AUTOSAR XML (schema 4-2-1)
package /StartApplication/StartApplication_swc/ComponentTypes
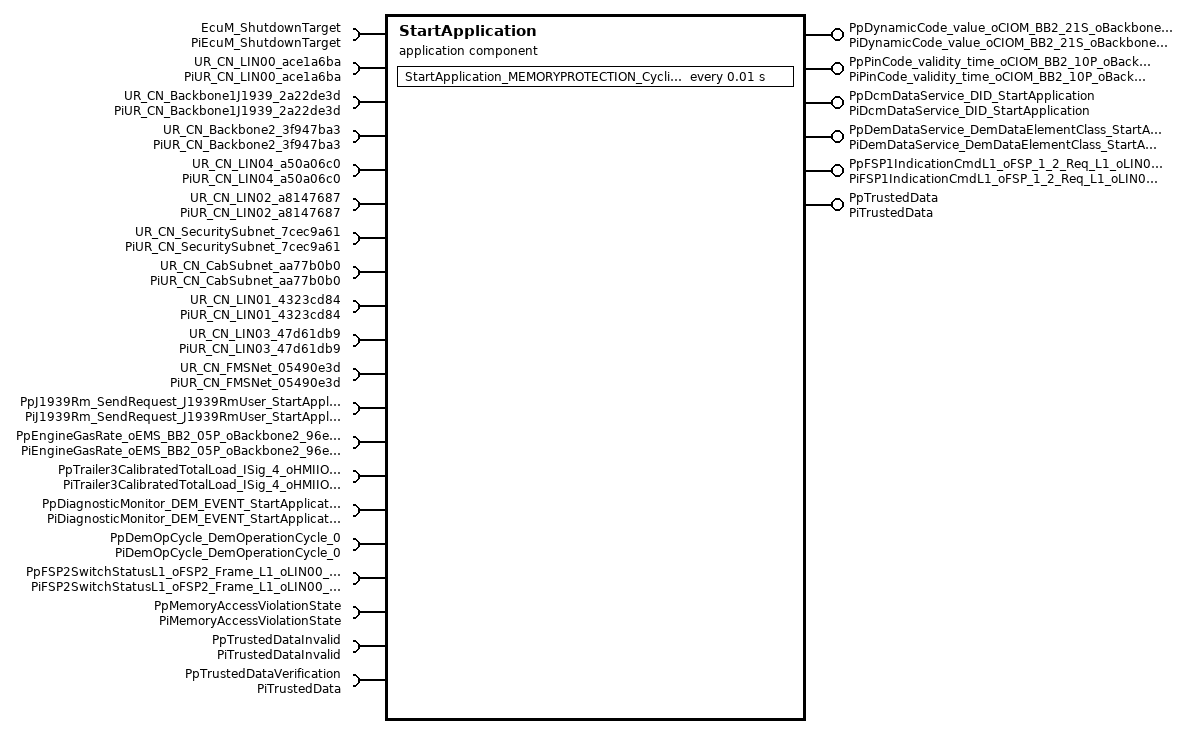
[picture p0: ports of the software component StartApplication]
  application sw component type StartApplication
    14 x require port:
      EcuM_ShutdownTarget: required-interface=PiEcuM_ShutdownTarget
      UR_CN_LIN00_ace1a6ba: required-interface=PiUR_CN_LIN00_ace1a6ba
      UR_CN_Backbone1J1939_2a22de3d: required-interface=PiUR_CN_Backbone1J1939_2a22de3d
      UR_CN_Backbone2_3f947ba3: required-interface=PiUR_CN_Backbone2_3f947ba3
      UR_CN_LIN04_a50a06c0: required-interface=PiUR_CN_LIN04_a50a06c0
      UR_CN_LIN02_a8147687: required-interface=PiUR_CN_LIN02_a8147687
      UR_CN_SecuritySubnet_7cec9a61: required-interface=PiUR_CN_SecuritySubnet_7cec9a61
      UR_CN_CabSubnet_aa77b0b0: required-interface=PiUR_CN_CabSubnet_aa77b0b0
      UR_CN_LIN01_4323cd84: required-interface=PiUR_CN_LIN01_4323cd84
      UR_CN_LIN03_47d61db9: required-interface=PiUR_CN_LIN03_47d61db9
      UR_CN_FMSNet_05490e3d: required-interface=PiUR_CN_FMSNet_05490e3d
      PpJ1939Rm_SendRequest_J1939RmUser_StartApplication: required-interface=PiJ1939Rm_SendRequest_J1939RmUser_StartApplication
      PpEngineGasRate_oEMS_BB2_05P_oBackbone2_96ec243f_Rx: nonqueued-receiver-com-spec{data-element=DeEngineGasRate_oEMS_BB2_05P_oBackbone2_96ec243f_Rx, handle-out-of-range-status=SILENT, init-value=65535}, required-interface=PiEngineGasRate_oEMS_BB2_05P_oBackbone2_96ec243f_Rx
      PpTrailer3CalibratedTotalLoad_ISig_4_oHMIIOM_BB2_15P_oBackbone2_a944db19_Rx: nonqueued-receiver-com-spec{data-element=DeTrailer3CalibratedTotalLoad_ISig_4_oHMIIOM_BB2_15P_oBackbone2_a944db19_Rx, handle-out-of-range-status=SILENT, init-value=65535}, required-interface=PiTrailer3CalibratedTotalLoad_ISig_4_oHMIIOM_BB2_15P_oBackbone2_a944db19_Rx
    provide port PpDynamicCode_value_oCIOM_BB2_21S_oBackbone2_04b10010_Tx: nonqueued-sender-com-spec{data-element=DeDynamicCode_value_oCIOM_BB2_21S_oBackbone2_04b10010_Tx, init-value=4294967295}, provided-interface=PiDynamicCode_value_oCIOM_BB2_21S_oBackbone2_04b10010_Tx
    provide port PpPinCode_validity_time_oCIOM_BB2_10P_oBackbone2_d8b8c81c_Tx: nonqueued-sender-com-spec{data-element=DePinCode_validity_time_oCIOM_BB2_10P_oBackbone2_d8b8c81c_Tx, init-value=255}, provided-interface=PiPinCode_validity_time_oCIOM_BB2_10P_oBackbone2_d8b8c81c_Tx
    require port PpDiagnosticMonitor_DEM_EVENT_StartApplication: required-interface=PiDiagnosticMonitor_DEM_EVENT_StartApplication
    provide port PpDcmDataService_DID_StartApplication: provided-interface=PiDcmDataService_DID_StartApplication
    provide port PpDemDataService_DemDataElementClass_StartApplication: provided-interface=PiDemDataService_DemDataElementClass_StartApplication
    require port PpDemOpCycle_DemOperationCycle_0: required-interface=PiDemOpCycle_DemOperationCycle_0
    provide port PpFSP1IndicationCmdL1_oFSP_1_2_Req_L1_oLIN00_c2c0fe90_Tx: nonqueued-sender-com-spec{data-element=DeFSP1IndicationCmdL1_oFSP_1_2_Req_L1_oLIN00_c2c0fe90_Tx, init-value=0}, provided-interface=PiFSP1IndicationCmdL1_oFSP_1_2_Req_L1_oLIN00_c2c0fe90_Tx
    require port PpFSP2SwitchStatusL1_oFSP2_Frame_L1_oLIN00_ee70e556_Rx: nonqueued-receiver-com-spec{data-element=DeFSP2SwitchStatusL1_oFSP2_Frame_L1_oLIN00_ee70e556_Rx, handle-out-of-range-status=SILENT, init-value=0}, required-interface=PiFSP2SwitchStatusL1_oFSP2_Frame_L1_oLIN00_ee70e556_Rx
    require port PpMemoryAccessViolationState: required-interface=PiMemoryAccessViolationState
    provide port PpTrustedData: nonqueued-sender-com-spec{data-element=DeValue, init-value=0}, provided-interface=PiTrustedData
    require port PpTrustedDataInvalid: required-interface=PiTrustedDataInvalid
    require port PpTrustedDataVerification: nonqueued-receiver-com-spec{data-element=DeValue, handle-out-of-range-status=SILENT, init-value=0}, required-interface=PiTrustedData
    behavior StartApplicationInternalBehavior: handle-termination-and-restart=NO-SUPPORT
      ar-typed-per-instance-memorys:
        14 x data:
          Uptime: type=uint8
          TxCtrlSigValue: type=uint8
          TxDataSigValue: type=uint8
          ActiveComponent: type=EnumActiveComponentType
          COM_RxSigValue0: type=uint16
          COM_TxSigValue0: type=uint8
          NM_ApplState: type=EnumNM_ApplStateType
          NM_ActiveChannelHasFullComRequest: type=uint8
          NM_BusSleepModeTimer: type=uint8
          NM_ActiveComMChannel: type=uint8
          NM_ActiveComMUsers: type=uint32
          DIAG_LastRxData: type=uint8
          COM_RxSigValue1: type=uint8
          COM_TxSigValue1: type=uint16
      4 x timing event:
        Timer_StartApplication_Cyclic1ms: start-on-event=StartApplication_Cyclic1ms, period=0.001
        Timer_StartApplication_Cyclic10ms: start-on-event=StartApplication_Cyclic10ms, period=0.01
        Timer_StartApplication_Cyclic250ms: start-on-event=StartApplication_Cyclic250ms, period=0.25
        Timer_StartApplication_Cyclic1000ms: start-on-event=StartApplication_Cyclic1000ms, period=1
      init event Timer_StartApplication_Init: start-on-event=StartApplication_Init
      data received event DataReceivedEvent_StartApplication_OnDataRec_RxData_PpEngineGasRate_oEMS_BB2_05P_oBackbone2_96ec243f_Rx_DeEngineGasRate_000974b3: start-on-event=StartApplication_OnDataRec_RxData, data=PpEngineGasRate_oEMS_BB2_05P_oBackbone2_96ec243f_Rx.DeEngineGasRate_oEMS_BB2_05P_oBackbone2_96ec243f_Rx
      data received event DataReceivedEvent_StartApplication_OnDataRec_RxCtrl_PpTrailer3CalibratedTotalLoad_ISig_4_oHMIIOM_BB2_15P_oBackbone2_a94_8da52e5b: start-on-event=StartApplication_OnDataRec_RxCtrl, data=PpTrailer3CalibratedTotalLoad_ISig_4_oHMIIOM_BB2_15P_oBackbone2_a944db19_Rx.DeTrailer3CalibratedTotalLoad_ISig_4_oHMIIOM_BB2_15P_oBackbone2_a944db19_Rx
      4 x operation invoked event:
        OpEventStartApplication_DIAG_DcmReadData_ReadData_PpDcmDataService_DID_StartApplication: start-on-event=StartApplication_DIAG_DcmReadData, operation=PpDcmDataService_DID_StartApplication.ReadData
        OpEventStartApplication_DIAG_DcmWriteData_WriteData_PpDcmDataService_DID_StartApplication: start-on-event=StartApplication_DIAG_DcmWriteData, operation=PpDcmDataService_DID_StartApplication.WriteData
        OpEventStartApplication_DIAG_ConditionCheckRead_ConditionCheckRead_PpDcmDataService_DID_StartApplication: start-on-event=StartApplication_DIAG_ConditionCheckRead, operation=PpDcmDataService_DID_StartApplication.ConditionCheckRead
        OpEventStartApplication_DIAG_DemReadData_ReadData_PpDemDataService_DemDataElementClass_StartApplication: start-on-event=StartApplication_DIAG_DemReadData, operation=PpDemDataService_DemDataElementClass_StartApplication.ReadData
      timing event Timer_StartApplication_MEMORYPROTECTION_Cyclic10ms: start-on-event=StartApplication_MEMORYPROTECTION_Cyclic10ms, period=0.01
      explicit-inter-runnable-variables:
        data IrvOccuranceCounterDid: type=uint16, init-value=0
        data IrvMemoryProtectionData: type=DtMemoryProtectionDataElementType, init-value=fields=[0, 0]
      port-api-options:
        enable-take-address=true, indirect-api=false, port=EcuM_ShutdownTarget
        enable-take-address=true, indirect-api=false, port=UR_CN_LIN00_ace1a6ba
        enable-take-address=true, indirect-api=false, port=UR_CN_Backbone1J1939_2a22de3d
        enable-take-address=true, indirect-api=false, port=UR_CN_Backbone2_3f947ba3
        enable-take-address=true, indirect-api=false, port=UR_CN_LIN04_a50a06c0
        enable-take-address=true, indirect-api=false, port=UR_CN_LIN02_a8147687
        enable-take-address=true, indirect-api=false, port=UR_CN_SecuritySubnet_7cec9a61
        enable-take-address=true, indirect-api=false, port=UR_CN_CabSubnet_aa77b0b0
        enable-take-address=true, indirect-api=false, port=UR_CN_LIN01_4323cd84
        enable-take-address=true, indirect-api=false, port=UR_CN_LIN03_47d61db9
        enable-take-address=true, indirect-api=false, port=UR_CN_FMSNet_05490e3d
        enable-take-address=true, indirect-api=false, port=PpJ1939Rm_SendRequest_J1939RmUser_StartApplication
        enable-take-address=true, indirect-api=false, port=PpEngineGasRate_oEMS_BB2_05P_oBackbone2_96ec243f_Rx
        enable-take-address=true, indirect-api=false, port=PpTrailer3CalibratedTotalLoad_ISig_4_oHMIIOM_BB2_15P_oBackbone2_a944db19_Rx
        enable-take-address=true, indirect-api=false, port=PpDynamicCode_value_oCIOM_BB2_21S_oBackbone2_04b10010_Tx
        enable-take-address=true, indirect-api=false, port=PpPinCode_validity_time_oCIOM_BB2_10P_oBackbone2_d8b8c81c_Tx
        enable-take-address=true, indirect-api=false, port=PpDiagnosticMonitor_DEM_EVENT_StartApplication
        enable-take-address=true, indirect-api=false, port=PpDcmDataService_DID_StartApplication
        enable-take-address=true, indirect-api=false, port=PpDemDataService_DemDataElementClass_StartApplication
        enable-take-address=true, indirect-api=false, port=PpDemOpCycle_DemOperationCycle_0
        enable-take-address=true, indirect-api=false, port=PpFSP1IndicationCmdL1_oFSP_1_2_Req_L1_oLIN00_c2c0fe90_Tx
        enable-take-address=true, indirect-api=false, port=PpFSP2SwitchStatusL1_oFSP2_Frame_L1_oLIN00_ee70e556_Rx
        enable-take-address=true, indirect-api=false, port=PpMemoryAccessViolationState
        enable-take-address=true, indirect-api=false, port=PpTrustedData
        enable-take-address=true, indirect-api=false, port=PpTrustedDataInvalid
        enable-take-address=true, indirect-api=false, port=PpTrustedDataVerification
      12 x runnable:
        StartApplication_Cyclic1ms
        StartApplication_Cyclic10ms
        StartApplication_Cyclic250ms
          data-receive-point-by-arguments:
            4 x access:
              DataReceivePointStartApplication_Cyclic250ms_PpEngineGasRate_oEMS_BB2_05P_oBackbone2_96ec243f_Rx_DeEngineGasRate_oEMS_B_ae04b97d: accessed-variable=PpEngineGasRate_oEMS_BB2_05P_oBackbone2_96ec243f_Rx.DeEngineGasRate_oEMS_BB2_05P_oBackbone2_96ec243f_Rx
              DataReceivePointStartApplication_Cyclic250ms_PpTrailer3CalibratedTotalLoad_ISig_4_oHMIIOM_BB2_15P_oBackbone2_a944db19_R_04086d7b: accessed-variable=PpTrailer3CalibratedTotalLoad_ISig_4_oHMIIOM_BB2_15P_oBackbone2_a944db19_Rx.DeTrailer3CalibratedTotalLoad_ISig_4_oHMIIOM_BB2_15P_oBackbone2_a944db19_Rx
              DataReceivePointStartApplication_Cyclic250ms_PpFSP2SwitchStatusL1_oFSP2_Frame_L1_oLIN00_ee70e556_Rx_DeFSP2SwitchStatusL_c96da29d: accessed-variable=PpFSP2SwitchStatusL1_oFSP2_Frame_L1_oLIN00_ee70e556_Rx.DeFSP2SwitchStatusL1_oFSP2_Frame_L1_oLIN00_ee70e556_Rx
              DataReceivePointStartApplication_Cyclic250ms_PpTrustedDataVerification_DeValue: accessed-variable=PpTrustedDataVerification.DeValue
          data-send-points:
            access DataSendPointStartApplication_Cyclic250ms_PpDynamicCode_value_oCIOM_BB2_21S_oBackbone2_04b10010_Tx_DeDynamicCode_value_b269f14a: accessed-variable=PpDynamicCode_value_oCIOM_BB2_21S_oBackbone2_04b10010_Tx.DeDynamicCode_value_oCIOM_BB2_21S_oBackbone2_04b10010_Tx
            access DataSendPointStartApplication_Cyclic250ms_PpPinCode_validity_time_oCIOM_BB2_10P_oBackbone2_d8b8c81c_Tx_DePinCode_validi_57f892c7: accessed-variable=PpPinCode_validity_time_oCIOM_BB2_10P_oBackbone2_d8b8c81c_Tx.DePinCode_validity_time_oCIOM_BB2_10P_oBackbone2_d8b8c81c_Tx
            access DataSendPointStartApplication_Cyclic250ms_PpFSP1IndicationCmdL1_oFSP_1_2_Req_L1_oLIN00_c2c0fe90_Tx_DeFSP1IndicationCmdL_f76876c0: accessed-variable=PpFSP1IndicationCmdL1_oFSP_1_2_Req_L1_oLIN00_c2c0fe90_Tx.DeFSP1IndicationCmdL1_oFSP_1_2_Req_L1_oLIN00_c2c0fe90_Tx
          read-local-variables:
            access StartApplication_Cyclic250ms_IrvOccuranceCounterDid_DIRECT_READ: accessed-variable=IrvOccuranceCounterDid
          22 x sync call, all with timeout=0:
            OpServerCallStartApplication_Cyclic250ms_GetCurrentComMode_UR_CN_LIN00_ace1a6ba: operation=UR_CN_LIN00_ace1a6ba.GetCurrentComMode
            OpServerCallStartApplication_Cyclic250ms_RequestComMode_UR_CN_LIN00_ace1a6ba: operation=UR_CN_LIN00_ace1a6ba.RequestComMode
            OpServerCallStartApplication_Cyclic250ms_GetCurrentComMode_UR_CN_Backbone1J1939_2a22de3d: operation=UR_CN_Backbone1J1939_2a22de3d.GetCurrentComMode
            OpServerCallStartApplication_Cyclic250ms_RequestComMode_UR_CN_Backbone1J1939_2a22de3d: operation=UR_CN_Backbone1J1939_2a22de3d.RequestComMode
            OpServerCallStartApplication_Cyclic250ms_GetCurrentComMode_UR_CN_Backbone2_3f947ba3: operation=UR_CN_Backbone2_3f947ba3.GetCurrentComMode
            OpServerCallStartApplication_Cyclic250ms_RequestComMode_UR_CN_Backbone2_3f947ba3: operation=UR_CN_Backbone2_3f947ba3.RequestComMode
            OpServerCallStartApplication_Cyclic250ms_GetCurrentComMode_UR_CN_LIN04_a50a06c0: operation=UR_CN_LIN04_a50a06c0.GetCurrentComMode
            OpServerCallStartApplication_Cyclic250ms_RequestComMode_UR_CN_LIN04_a50a06c0: operation=UR_CN_LIN04_a50a06c0.RequestComMode
            OpServerCallStartApplication_Cyclic250ms_GetCurrentComMode_UR_CN_LIN02_a8147687: operation=UR_CN_LIN02_a8147687.GetCurrentComMode
            OpServerCallStartApplication_Cyclic250ms_RequestComMode_UR_CN_LIN02_a8147687: operation=UR_CN_LIN02_a8147687.RequestComMode
            OpServerCallStartApplication_Cyclic250ms_GetCurrentComMode_UR_CN_SecuritySubnet_7cec9a61: operation=UR_CN_SecuritySubnet_7cec9a61.GetCurrentComMode
            OpServerCallStartApplication_Cyclic250ms_RequestComMode_UR_CN_SecuritySubnet_7cec9a61: operation=UR_CN_SecuritySubnet_7cec9a61.RequestComMode
            OpServerCallStartApplication_Cyclic250ms_GetCurrentComMode_UR_CN_CabSubnet_aa77b0b0: operation=UR_CN_CabSubnet_aa77b0b0.GetCurrentComMode
            OpServerCallStartApplication_Cyclic250ms_RequestComMode_UR_CN_CabSubnet_aa77b0b0: operation=UR_CN_CabSubnet_aa77b0b0.RequestComMode
            OpServerCallStartApplication_Cyclic250ms_GetCurrentComMode_UR_CN_LIN01_4323cd84: operation=UR_CN_LIN01_4323cd84.GetCurrentComMode
            OpServerCallStartApplication_Cyclic250ms_RequestComMode_UR_CN_LIN01_4323cd84: operation=UR_CN_LIN01_4323cd84.RequestComMode
            OpServerCallStartApplication_Cyclic250ms_GetCurrentComMode_UR_CN_LIN03_47d61db9: operation=UR_CN_LIN03_47d61db9.GetCurrentComMode
            OpServerCallStartApplication_Cyclic250ms_RequestComMode_UR_CN_LIN03_47d61db9: operation=UR_CN_LIN03_47d61db9.RequestComMode
            OpServerCallStartApplication_Cyclic250ms_GetCurrentComMode_UR_CN_FMSNet_05490e3d: operation=UR_CN_FMSNet_05490e3d.GetCurrentComMode
            OpServerCallStartApplication_Cyclic250ms_RequestComMode_UR_CN_FMSNet_05490e3d: operation=UR_CN_FMSNet_05490e3d.RequestComMode
            OpServerCallStartApplication_Cyclic250ms_SendRequest_PpJ1939Rm_SendRequest_J1939RmUser_StartApplication: operation=PpJ1939Rm_SendRequest_J1939RmUser_StartApplication.SendRequest
            OpServerCallStartApplication_Cyclic250ms_GetState_PpMemoryAccessViolationState: operation=PpMemoryAccessViolationState.GetState
        StartApplication_Cyclic1000ms
        StartApplication_Init: can-be-invoked-concurrently=true
          10 x sync call, all with timeout=0:
            OpServerCallStartApplication_Init_RequestComMode_UR_CN_LIN00_ace1a6ba: operation=UR_CN_LIN00_ace1a6ba.RequestComMode
            OpServerCallStartApplication_Init_RequestComMode_UR_CN_Backbone1J1939_2a22de3d: operation=UR_CN_Backbone1J1939_2a22de3d.RequestComMode
            OpServerCallStartApplication_Init_RequestComMode_UR_CN_Backbone2_3f947ba3: operation=UR_CN_Backbone2_3f947ba3.RequestComMode
            OpServerCallStartApplication_Init_RequestComMode_UR_CN_LIN04_a50a06c0: operation=UR_CN_LIN04_a50a06c0.RequestComMode
            OpServerCallStartApplication_Init_RequestComMode_UR_CN_LIN02_a8147687: operation=UR_CN_LIN02_a8147687.RequestComMode
            OpServerCallStartApplication_Init_RequestComMode_UR_CN_SecuritySubnet_7cec9a61: operation=UR_CN_SecuritySubnet_7cec9a61.RequestComMode
            OpServerCallStartApplication_Init_RequestComMode_UR_CN_CabSubnet_aa77b0b0: operation=UR_CN_CabSubnet_aa77b0b0.RequestComMode
            OpServerCallStartApplication_Init_RequestComMode_UR_CN_LIN01_4323cd84: operation=UR_CN_LIN01_4323cd84.RequestComMode
            OpServerCallStartApplication_Init_RequestComMode_UR_CN_LIN03_47d61db9: operation=UR_CN_LIN03_47d61db9.RequestComMode
            OpServerCallStartApplication_Init_RequestComMode_UR_CN_FMSNet_05490e3d: operation=UR_CN_FMSNet_05490e3d.RequestComMode
        StartApplication_OnDataRec_RxCtrl
          data-receive-point-by-arguments:
            access DataReceivePointStartApplication_OnDataRec_RxCtrl_PpTrailer3CalibratedTotalLoad_ISig_4_oHMIIOM_BB2_15P_oBackbone2_a944d_33d96471: accessed-variable=PpTrailer3CalibratedTotalLoad_ISig_4_oHMIIOM_BB2_15P_oBackbone2_a944db19_Rx.DeTrailer3CalibratedTotalLoad_ISig_4_oHMIIOM_BB2_15P_oBackbone2_a944db19_Rx
          data-send-points:
            access DataSendPointStartApplication_OnDataRec_RxCtrl_PpDynamicCode_value_oCIOM_BB2_21S_oBackbone2_04b10010_Tx_DeDynamicCode_v_6366352b: accessed-variable=PpDynamicCode_value_oCIOM_BB2_21S_oBackbone2_04b10010_Tx.DeDynamicCode_value_oCIOM_BB2_21S_oBackbone2_04b10010_Tx
          sync call OpServerCallStartApplication_OnDataRec_RxCtrl_SetOperationCycleState_PpDemOpCycle_DemOperationCycle_0: operation=PpDemOpCycle_DemOperationCycle_0.SetOperationCycleState, timeout=0
        StartApplication_OnDataRec_RxData
          data-receive-point-by-arguments:
            access DataReceivePointStartApplication_OnDataRec_RxData_PpEngineGasRate_oEMS_BB2_05P_oBackbone2_96ec243f_Rx_DeEngineGasRate_o_5e0bb4c8: accessed-variable=PpEngineGasRate_oEMS_BB2_05P_oBackbone2_96ec243f_Rx.DeEngineGasRate_oEMS_BB2_05P_oBackbone2_96ec243f_Rx
          data-send-points:
            access DataSendPointStartApplication_OnDataRec_RxData_PpDynamicCode_value_oCIOM_BB2_21S_oBackbone2_04b10010_Tx_DeDynamicCode_v_8dc24bf2: accessed-variable=PpDynamicCode_value_oCIOM_BB2_21S_oBackbone2_04b10010_Tx.DeDynamicCode_value_oCIOM_BB2_21S_oBackbone2_04b10010_Tx
            access DataSendPointStartApplication_OnDataRec_RxData_PpTrustedData_DeValue: accessed-variable=PpTrustedData.DeValue
          read-local-variables:
            access StartApplication_OnDataRec_RxData_IrvOccuranceCounterDid_DIRECT_READ: accessed-variable=IrvOccuranceCounterDid
          sync call OpServerCallStartApplication_OnDataRec_RxData_SelectShutdownTarget_EcuM_ShutdownTarget: operation=EcuM_ShutdownTarget.SelectShutdownTarget, timeout=0
          sync call OpServerCallStartApplication_OnDataRec_RxData_SetEventStatus_PpDiagnosticMonitor_DEM_EVENT_StartApplication: operation=PpDiagnosticMonitor_DEM_EVENT_StartApplication.SetEventStatus, timeout=0
          sync call OpServerCallStartApplication_OnDataRec_RxData_Reset_PpMemoryAccessViolationState: operation=PpMemoryAccessViolationState.Reset, timeout=0
          written-local-variables:
            access StartApplication_OnDataRec_RxData_IrvOccuranceCounterDid_DIRECT_WRITE: accessed-variable=IrvOccuranceCounterDid
            access StartApplication_OnDataRec_RxData_IrvMemoryProtectionData_DIRECT_WRITE: accessed-variable=IrvMemoryProtectionData
        StartApplication_DIAG_DcmReadData: can-be-invoked-concurrently=true
          read-local-variables:
            access StartApplication_DIAG_DcmReadData_IrvOccuranceCounterDid_DIRECT_READ: accessed-variable=IrvOccuranceCounterDid
        StartApplication_DIAG_DcmWriteData: can-be-invoked-concurrently=true
          written-local-variables:
            access StartApplication_DIAG_DcmWriteData_IrvOccuranceCounterDid_DIRECT_WRITE: accessed-variable=IrvOccuranceCounterDid
        StartApplication_DIAG_ConditionCheckRead: can-be-invoked-concurrently=true
        StartApplication_DIAG_DemReadData: can-be-invoked-concurrently=true
          read-local-variables:
            access StartApplication_DIAG_DemReadData_IrvOccuranceCounterDid_DIRECT_READ: accessed-variable=IrvOccuranceCounterDid
        StartApplication_MEMORYPROTECTION_Cyclic10ms
          read-local-variables:
            access StartApplication_MEMORYPROTECTION_Cyclic10ms_IrvMemoryProtectionData_DIRECT_READ: accessed-variable=IrvMemoryProtectionData
          sync call OpServerCallStartApplication_MEMORYPROTECTION_Cyclic10ms_Write_PpTrustedDataInvalid: operation=PpTrustedDataInvalid.Write, timeout=0
          written-local-variables:
            access StartApplication_MEMORYPROTECTION_Cyclic10ms_IrvMemoryProtectionData_DIRECT_WRITE: accessed-variable=IrvMemoryProtectionData
  swc implementation StartApplicationImplementation: programming-language=C, behavior=StartApplicationInternalBehavior
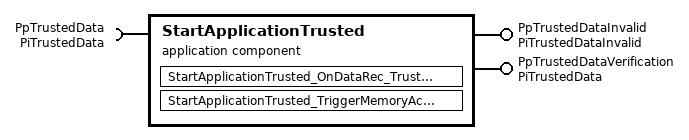
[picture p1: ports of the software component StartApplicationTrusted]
  application sw component type StartApplicationTrusted
    require port PpTrustedData: nonqueued-receiver-com-spec{data-element=DeValue, handle-out-of-range-status=SILENT, init-value=0}, required-interface=PiTrustedData
    provide port PpTrustedDataInvalid: server-com-spec{operation=Write, queue-length=1}, provided-interface=PiTrustedDataInvalid
    provide port PpTrustedDataVerification: nonqueued-sender-com-spec{data-element=DeValue, init-value=0}, provided-interface=PiTrustedData
    behavior StartApplicationTrustedInternalBehavior: handle-termination-and-restart=NO-SUPPORT
      data received event DataReceivedEvent_StartApplicationTrusted_OnDataRec_TrustedData_PpTrustedData_DeValue: start-on-event=StartApplicationTrusted_OnDataRec_TrustedData, data=PpTrustedData.DeValue
      operation invoked event OpEventStartApplicationTrusted_TriggerMemoryAccesViolation_Write_PpTrustedDataInvalid: start-on-event=StartApplicationTrusted_TriggerMemoryAccesViolation, operation=PpTrustedDataInvalid.Write
      explicit-inter-runnable-variables:
        data IrvValue: type=uint8, init-value=0
      port-api-options:
        enable-take-address=true, indirect-api=false, port=PpTrustedData
        enable-take-address=true, indirect-api=false, port=PpTrustedDataInvalid
        enable-take-address=true, indirect-api=false, port=PpTrustedDataVerification
      runnable StartApplicationTrusted_OnDataRec_TrustedData
        data-receive-point-by-arguments:
          access DataReceivePointStartApplicationTrusted_OnDataRec_TrustedData_PpTrustedData_DeValue: accessed-variable=PpTrustedData.DeValue
        data-send-points:
          access DataSendPointStartApplicationTrusted_OnDataRec_TrustedData_PpTrustedDataVerification_DeValue: accessed-variable=PpTrustedDataVerification.DeValue
        read-local-variables:
          access StartApplicationTrusted_OnDataRec_TrustedData_IrvValue_DIRECT_READ: accessed-variable=IrvValue
        written-local-variables:
          access StartApplicationTrusted_OnDataRec_TrustedData_IrvValue_DIRECT_WRITE: accessed-variable=IrvValue
      runnable StartApplicationTrusted_TriggerMemoryAccesViolation
        data-send-points:
          access DataSendPointStartApplicationTrusted_TriggerMemoryAccesViolation_PpTrustedDataVerification_DeValue: accessed-variable=PpTrustedDataVerification.DeValue
        read-local-variables:
          access StartApplicationTrusted_TriggerMemoryAccesViolation_IrvValue_DIRECT_READ: accessed-variable=IrvValue
        written-local-variables:
          access StartApplicationTrusted_TriggerMemoryAccesViolation_IrvValue_DIRECT_WRITE: accessed-variable=IrvValue
  swc implementation StartApplicationTrustedImplementation: programming-language=C, behavior=StartApplicationTrustedInternalBehavior
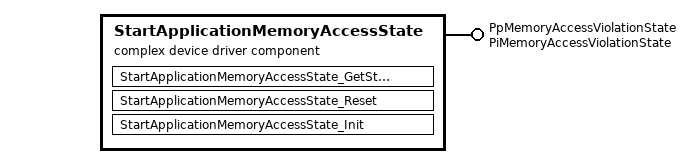
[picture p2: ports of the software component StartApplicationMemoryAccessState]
  complex device driver sw component type StartApplicationMemoryAccessState
    provide port PpMemoryAccessViolationState: provided-com-specs=[{operation=GetState, queue-length=1}, {operation=Reset, queue-length=1}], provided-interface=PiMemoryAccessViolationState
    behavior StartApplicationMemoryAccessStateInternalBehavior: handle-termination-and-restart=NO-SUPPORT, port-api-option{enable-take-address=true, indirect-api=false, port=PpMemoryAccessViolationState}
      ar-typed-per-instance-memorys:
        data PimMemoryAccessState: type=boolean
      operation invoked event OpEventStartApplicationMemoryAccessState_GetState_GetState_PpMemoryAccessViolationState: start-on-event=StartApplicationMemoryAccessState_GetState, operation=PpMemoryAccessViolationState.GetState
      operation invoked event OpEventStartApplicationMemoryAccessState_Reset_Reset_PpMemoryAccessViolationState: start-on-event=StartApplicationMemoryAccessState_Reset, operation=PpMemoryAccessViolationState.Reset
      init event Timer_StartApplicationMemoryAccessState_Init: start-on-event=StartApplicationMemoryAccessState_Init
      runnable StartApplicationMemoryAccessState_GetState
      runnable StartApplicationMemoryAccessState_Reset
      runnable StartApplicationMemoryAccessState_Init: can-be-invoked-concurrently=true
  swc implementation StartApplicationMemoryAccessStateImplementation: programming-language=C, behavior=StartApplicationMemoryAccessStateInternalBehavior
package /StartApplication/StartApplication_swc/DataTypes
  15 x impl type:
    EcuM_StateType:
      compu {15=ECUM_SUBSTATE_MASK, 16=ECUM_STATE_STARTUP, 17=ECUM_STATE_STARTUP_ONE, 18=ECUM_STATE_STARTUP_TWO, 32=ECUM_STATE_WAKEUP, 33=ECUM_STATE_WAKEUP_ONE, 34=ECUM_STATE_WAKEUP_VALIDATION, 35=ECUM_STATE_WAKEUP_REACTION, 36=ECUM_STATE_WAKEUP_TWO, 37=ECUM_STATE_WAKEUP_WAKESLEEP, 38=ECUM_STATE_WAKEUP_TTII, 48=ECUM_STATE_RUN, 50=ECUM_STATE_APP_RUN, 51=ECUM_STATE_APP_POST_RUN, 64=ECUM_STATE_SHUTDOWN, 68=ECUM_STATE_PREP_SHUTDOWN, 73=ECUM_STATE_GO_SLEEP, 77=ECUM_STATE_GO_OFF_ONE, 78=ECUM_STATE_GO_OFF_TWO, 80=ECUM_STATE_SLEEP, 128=ECUM_STATE_OFF, 144=ECUM_STATE_RESET}
      range raw 0..144
      implementation-data-type=uint8
    EcuM_SleepModeType: implementation-data-type=uint8
    EcuM_ShutdownCauseType: compu {0=ECUM_CAUSE_UNKNOWN, 1=ECUM_CAUSE_ECU_STATE, 2=ECUM_CAUSE_WDGM, 3=ECUM_CAUSE_DCM}, range raw 0..3, implementation-data-type=uint8
    ComM_ModeType: compu {0=COMM_NO_COMMUNICATION, 1=COMM_SILENT_COMMUNICATION, 2=COMM_FULL_COMMUNICATION}, range raw 0..2, implementation-data-type=uint8
    NetworkHandleType: implementation-data-type=uint8, type-emitter=StartApplication
    J1939Rm_ExtIdType: compu {0=J1939RM_EXTID_NONE, 1=J1939RM_EXTID_ONE, 2=J1939RM_EXTID_TWO, 3=J1939RM_EXTID_THREE, 4=J1939RM_EXTID_GF}, range raw 0..4, implementation-data-type=uint8
    J1939Rm_ExtIdInfoType: category=STRUCTURE
      4 x element, all with category=TYPE_REFERENCE:
        ExtIdType: implementation-data-type=J1939Rm_ExtIdType
        ExtId{1..3}: implementation-data-type=uint8
    EnumNM_ApplStateType: compu {0=NM_APPL_STATE_FULL_COMM_EXTERN, 1=NM_APPL_STATE_FULL_COMM_INTERN, 2=NM_APPL_STATE_NO_COMM_EXTERN}, range raw 0..2, implementation-data-type=uint8
    Dem_EventStatusType: compu {0=DEM_EVENT_STATUS_PASSED, 1=DEM_EVENT_STATUS_FAILED, 2=DEM_EVENT_STATUS_PREPASSED, 3=DEM_EVENT_STATUS_PREFAILED, 4=DEM_EVENT_STATUS_FDC_THRESHOLD_REACHED}, range raw 0..4, implementation-data-type=uint8
    Dcm_Data2ByteType: category=ARRAY, sw-calibration-access=READ-ONLY
      element Dcm_Data2ByteTypeElement: array-size=2, array-size-semantics=FIXED-SIZE, implementation-data-type=uint8
    Dcm_NegativeResponseCodeType:
      compu {0=DCM_E_POSITIVERESPONSE, 16=DCM_E_GENERALREJECT, 17=DCM_E_SERVICENOTSUPPORTED, 18=DCM_E_SUBFUNCTIONNOTSUPPORTED, 19=DCM_E_INCORRECTMESSAGELENGTHORINVALIDFORMAT, 20=DCM_E_RESPONSETOOLONG, 33=DCM_E_BUSYREPEATREQUEST, 34=DCM_E_CONDITIONSNOTCORRECT, 36=DCM_E_REQUESTSEQUENCEERROR, 37=DCM_E_NORESPONSEFROMSUBNETCOMPONENT, 38=DCM_E_FAILUREPREVENTSEXECUTIONOFREQUESTEDACTION, 49=DCM_E_REQUESTOUTOFRANGE, 51=DCM_E_SECURITYACCESSDENIED, 53=DCM_E_INVALIDKEY, 54=DCM_E_EXCEEDNUMBEROFATTEMPTS, 55=DCM_E_REQUIREDTIMEDELAYNOTEXPIRED, 112=DCM_E_UPLOADDOWNLOADNOTACCEPTED, 113=DCM_E_TRANSFERDATASUSPENDED, 114=DCM_E_GENERALPROGRAMMINGFAILURE, 115=DCM_E_WRONGBLOCKSEQUENCECOUNTER, 120=DCM_E_REQUESTCORRECTLYRECEIVEDRESPONSEPENDING, 126=DCM_E_SUBFUNCTIONNOTSUPPORTEDINACTIVESESSION, 127=DCM_E_SERVICENOTSUPPORTEDINACTIVESESSION, 129=DCM_E_RPMTOOHIGH, 130=DCM_E_RPMTOOLOW, 131=DCM_E_ENGINEISRUNNING, 132=DCM_E_ENGINEISNOTRUNNING, 133=DCM_E_ENGINERUNTIMETOOLOW, 134=DCM_E_TEMPERATURETOOHIGH, 135=DCM_E_TEMPERATURETOOLOW, 136=DCM_E_VEHICLESPEEDTOOHIGH, 137=DCM_E_VEHICLESPEEDTOOLOW, 138=DCM_E_THROTTLE_PEDALTOOHIGH, 139=DCM_E_THROTTLE_PEDALTOOLOW, 140=DCM_E_TRANSMISSIONRANGENOTINNEUTRAL, 141=DCM_E_TRANSMISSIONRANGENOTINGEAR, 143=DCM_E_BRAKESWITCH_NOTCLOSED, 144=DCM_E_SHIFTERLEVERNOTINPARK, 145=DCM_E_TORQUECONVERTERCLUTCHLOCKED, 146=DCM_E_VOLTAGETOOHIGH, 147=DCM_E_VOLTAGETOOLOW}
      range raw 0..147
      implementation-data-type=uint8
    DataArray_Type_2: category=ARRAY, sw-calibration-access=READ-ONLY
      element DataArray_Type_2Element: array-size=2, array-size-semantics=FIXED-SIZE, implementation-data-type=uint8
    Dem_OperationCycleStateType: compu {0=DEM_CYCLE_STATE_START, 1=DEM_CYCLE_STATE_END}, range raw 0..1, implementation-data-type=uint8
    DtMemoryProtectionDataElementType: category=STRUCTURE
      element Value: implementation-data-type=uint8
      element InvalidAccess: implementation-data-type=boolean
    EnumActiveComponentType: compu {0=STARTAPPLICATION_ACTIVE_COMPONENT_COM_RXTX, 2=STARTAPPLICATION_ACTIVE_COMPONENT_DIAG, 3=STARTAPPLICATION_ACTIVE_COMPONENT_COM_TXONLY, 9=STARTAPPLICATION_ACTIVE_COMPONENT_MEMORYPROTECTION, 10=STARTAPPLICATION_ACTIVE_COMPONENT_NM, 255=STARTAPPLICATION_ACTIVE_COMPONENT_INVALID}, range raw 0..255, implementation-data-type=uint8
package /StartApplication/StartApplication_swc/Interfaces
  sender receiver interface PiGeneric
    data DeGeneric: type=uint8
  12 x client server interface, all with is-service=true, service-kind=VENDOR-SPECIFIC:
    PiEcuM_ShutdownTarget
      5 x operation, all with possible-error=PiEcuM_ShutdownTarget/E_NOT_OK:
        SelectShutdownTarget
          arg targetState: type=EcuM_StateType, direction=IN
          arg resetSleepMode: type=EcuM_SleepModeType, direction=IN
        GetShutdownTarget
          arg target: type=EcuM_StateType, direction=OUT
          arg resetSleepMode: type=EcuM_SleepModeType, direction=OUT
        GetLastShutdownTarget
          arg target: type=EcuM_StateType, direction=OUT
          arg resetSleepMode: type=EcuM_SleepModeType, direction=OUT
        SelectShutdownCause
          arg shutdownCause: type=EcuM_ShutdownCauseType, direction=IN
        GetShutdownCause
          arg shutdownCause: type=EcuM_ShutdownCauseType, direction=OUT
      error E_NOT_OK: error-code=1
    PiUR_CN_LIN00_ace1a6ba
      4 x operation:
        GetCurrentComMode: possible-error=PiUR_CN_LIN00_ace1a6ba/E_NOT_OK
          arg ComMode: type=ComM_ModeType, direction=OUT
        GetMaxComMode: possible-error=PiUR_CN_LIN00_ace1a6ba/E_NOT_OK
          arg ComMode: type=ComM_ModeType, direction=OUT
        GetRequestedComMode: possible-error=PiUR_CN_LIN00_ace1a6ba/E_NOT_OK
          arg ComMode: type=ComM_ModeType, direction=OUT
        RequestComMode: possible-error=[PiUR_CN_LIN00_ace1a6ba/E_NOT_OK, PiUR_CN_LIN00_ace1a6ba/E_MODE_LIMITATION]
          arg ComMode: type=ComM_ModeType, direction=IN
      error E_NOT_OK: error-code=1
      error E_MODE_LIMITATION: error-code=2
    PiUR_CN_Backbone1J1939_2a22de3d
      4 x operation:
        GetCurrentComMode: possible-error=PiUR_CN_Backbone1J1939_2a22de3d/E_NOT_OK
          arg ComMode: type=ComM_ModeType, direction=OUT
        GetMaxComMode: possible-error=PiUR_CN_Backbone1J1939_2a22de3d/E_NOT_OK
          arg ComMode: type=ComM_ModeType, direction=OUT
        GetRequestedComMode: possible-error=PiUR_CN_Backbone1J1939_2a22de3d/E_NOT_OK
          arg ComMode: type=ComM_ModeType, direction=OUT
        RequestComMode: possible-error=[PiUR_CN_Backbone1J1939_2a22de3d/E_NOT_OK, PiUR_CN_Backbone1J1939_2a22de3d/E_MODE_LIMITATION]
          arg ComMode: type=ComM_ModeType, direction=IN
      error E_NOT_OK: error-code=1
      error E_MODE_LIMITATION: error-code=2
    PiUR_CN_Backbone2_3f947ba3
      4 x operation:
        GetCurrentComMode: possible-error=PiUR_CN_Backbone2_3f947ba3/E_NOT_OK
          arg ComMode: type=ComM_ModeType, direction=OUT
        GetMaxComMode: possible-error=PiUR_CN_Backbone2_3f947ba3/E_NOT_OK
          arg ComMode: type=ComM_ModeType, direction=OUT
        GetRequestedComMode: possible-error=PiUR_CN_Backbone2_3f947ba3/E_NOT_OK
          arg ComMode: type=ComM_ModeType, direction=OUT
        RequestComMode: possible-error=[PiUR_CN_Backbone2_3f947ba3/E_NOT_OK, PiUR_CN_Backbone2_3f947ba3/E_MODE_LIMITATION]
          arg ComMode: type=ComM_ModeType, direction=IN
      error E_NOT_OK: error-code=1
      error E_MODE_LIMITATION: error-code=2
    PiUR_CN_LIN04_a50a06c0
      4 x operation:
        GetCurrentComMode: possible-error=PiUR_CN_LIN04_a50a06c0/E_NOT_OK
          arg ComMode: type=ComM_ModeType, direction=OUT
        GetMaxComMode: possible-error=PiUR_CN_LIN04_a50a06c0/E_NOT_OK
          arg ComMode: type=ComM_ModeType, direction=OUT
        GetRequestedComMode: possible-error=PiUR_CN_LIN04_a50a06c0/E_NOT_OK
          arg ComMode: type=ComM_ModeType, direction=OUT
        RequestComMode: possible-error=[PiUR_CN_LIN04_a50a06c0/E_NOT_OK, PiUR_CN_LIN04_a50a06c0/E_MODE_LIMITATION]
          arg ComMode: type=ComM_ModeType, direction=IN
      error E_NOT_OK: error-code=1
      error E_MODE_LIMITATION: error-code=2
    PiUR_CN_LIN02_a8147687
      4 x operation:
        GetCurrentComMode: possible-error=PiUR_CN_LIN02_a8147687/E_NOT_OK
          arg ComMode: type=ComM_ModeType, direction=OUT
        GetMaxComMode: possible-error=PiUR_CN_LIN02_a8147687/E_NOT_OK
          arg ComMode: type=ComM_ModeType, direction=OUT
        GetRequestedComMode: possible-error=PiUR_CN_LIN02_a8147687/E_NOT_OK
          arg ComMode: type=ComM_ModeType, direction=OUT
        RequestComMode: possible-error=[PiUR_CN_LIN02_a8147687/E_NOT_OK, PiUR_CN_LIN02_a8147687/E_MODE_LIMITATION]
          arg ComMode: type=ComM_ModeType, direction=IN
      error E_NOT_OK: error-code=1
      error E_MODE_LIMITATION: error-code=2
    PiUR_CN_SecuritySubnet_7cec9a61
      4 x operation:
        GetCurrentComMode: possible-error=PiUR_CN_SecuritySubnet_7cec9a61/E_NOT_OK
          arg ComMode: type=ComM_ModeType, direction=OUT
        GetMaxComMode: possible-error=PiUR_CN_SecuritySubnet_7cec9a61/E_NOT_OK
          arg ComMode: type=ComM_ModeType, direction=OUT
        GetRequestedComMode: possible-error=PiUR_CN_SecuritySubnet_7cec9a61/E_NOT_OK
          arg ComMode: type=ComM_ModeType, direction=OUT
        RequestComMode: possible-error=[PiUR_CN_SecuritySubnet_7cec9a61/E_NOT_OK, PiUR_CN_SecuritySubnet_7cec9a61/E_MODE_LIMITATION]
          arg ComMode: type=ComM_ModeType, direction=IN
      error E_NOT_OK: error-code=1
      error E_MODE_LIMITATION: error-code=2
    PiUR_CN_CabSubnet_aa77b0b0
      4 x operation:
        GetCurrentComMode: possible-error=PiUR_CN_CabSubnet_aa77b0b0/E_NOT_OK
          arg ComMode: type=ComM_ModeType, direction=OUT
        GetMaxComMode: possible-error=PiUR_CN_CabSubnet_aa77b0b0/E_NOT_OK
          arg ComMode: type=ComM_ModeType, direction=OUT
        GetRequestedComMode: possible-error=PiUR_CN_CabSubnet_aa77b0b0/E_NOT_OK
          arg ComMode: type=ComM_ModeType, direction=OUT
        RequestComMode: possible-error=[PiUR_CN_CabSubnet_aa77b0b0/E_NOT_OK, PiUR_CN_CabSubnet_aa77b0b0/E_MODE_LIMITATION]
          arg ComMode: type=ComM_ModeType, direction=IN
      error E_NOT_OK: error-code=1
      error E_MODE_LIMITATION: error-code=2
    PiUR_CN_LIN01_4323cd84
      4 x operation:
        GetCurrentComMode: possible-error=PiUR_CN_LIN01_4323cd84/E_NOT_OK
          arg ComMode: type=ComM_ModeType, direction=OUT
        GetMaxComMode: possible-error=PiUR_CN_LIN01_4323cd84/E_NOT_OK
          arg ComMode: type=ComM_ModeType, direction=OUT
        GetRequestedComMode: possible-error=PiUR_CN_LIN01_4323cd84/E_NOT_OK
          arg ComMode: type=ComM_ModeType, direction=OUT
        RequestComMode: possible-error=[PiUR_CN_LIN01_4323cd84/E_NOT_OK, PiUR_CN_LIN01_4323cd84/E_MODE_LIMITATION]
          arg ComMode: type=ComM_ModeType, direction=IN
      error E_NOT_OK: error-code=1
      error E_MODE_LIMITATION: error-code=2
    PiUR_CN_LIN03_47d61db9
      4 x operation:
        GetCurrentComMode: possible-error=PiUR_CN_LIN03_47d61db9/E_NOT_OK
          arg ComMode: type=ComM_ModeType, direction=OUT
        GetMaxComMode: possible-error=PiUR_CN_LIN03_47d61db9/E_NOT_OK
          arg ComMode: type=ComM_ModeType, direction=OUT
        GetRequestedComMode: possible-error=PiUR_CN_LIN03_47d61db9/E_NOT_OK
          arg ComMode: type=ComM_ModeType, direction=OUT
        RequestComMode: possible-error=[PiUR_CN_LIN03_47d61db9/E_NOT_OK, PiUR_CN_LIN03_47d61db9/E_MODE_LIMITATION]
          arg ComMode: type=ComM_ModeType, direction=IN
      error E_NOT_OK: error-code=1
      error E_MODE_LIMITATION: error-code=2
    PiUR_CN_FMSNet_05490e3d
      4 x operation:
        GetCurrentComMode: possible-error=PiUR_CN_FMSNet_05490e3d/E_NOT_OK
          arg ComMode: type=ComM_ModeType, direction=OUT
        GetMaxComMode: possible-error=PiUR_CN_FMSNet_05490e3d/E_NOT_OK
          arg ComMode: type=ComM_ModeType, direction=OUT
        GetRequestedComMode: possible-error=PiUR_CN_FMSNet_05490e3d/E_NOT_OK
          arg ComMode: type=ComM_ModeType, direction=OUT
        RequestComMode: possible-error=[PiUR_CN_FMSNet_05490e3d/E_NOT_OK, PiUR_CN_FMSNet_05490e3d/E_MODE_LIMITATION]
          arg ComMode: type=ComM_ModeType, direction=IN
      error E_NOT_OK: error-code=1
      error E_MODE_LIMITATION: error-code=2
    PiJ1939Rm_SendRequest_J1939RmUser_StartApplication
      operation SendRequest: possible-error=PiJ1939Rm_SendRequest_J1939RmUser_StartApplication/E_NOT_OK
        6 x arg, all with direction=IN:
          channel: type=NetworkHandleType
          requestedPgn: type=uint32
          extIdInfo: type=J1939Rm_ExtIdInfoType
          destAddress: type=uint8
          priority: type=uint8
          checkTimeout: type=boolean
      error E_NOT_OK: error-code=1
  4 x sender receiver interface:
    PiEngineGasRate_oEMS_BB2_05P_oBackbone2_96ec243f_Rx
      data DeEngineGasRate_oEMS_BB2_05P_oBackbone2_96ec243f_Rx: type=uint16
    PiTrailer3CalibratedTotalLoad_ISig_4_oHMIIOM_BB2_15P_oBackbone2_a944db19_Rx
      data DeTrailer3CalibratedTotalLoad_ISig_4_oHMIIOM_BB2_15P_oBackbone2_a944db19_Rx: type=uint16
    PiDynamicCode_value_oCIOM_BB2_21S_oBackbone2_04b10010_Tx
      data DeDynamicCode_value_oCIOM_BB2_21S_oBackbone2_04b10010_Tx: type=uint32
    PiPinCode_validity_time_oCIOM_BB2_10P_oBackbone2_d8b8c81c_Tx
      data DePinCode_validity_time_oCIOM_BB2_10P_oBackbone2_d8b8c81c_Tx: type=uint8
  4 x client server interface, all with is-service=true, service-kind=VENDOR-SPECIFIC:
    PiDiagnosticMonitor_DEM_EVENT_StartApplication
      operation SetEventStatus: possible-error=PiDiagnosticMonitor_DEM_EVENT_StartApplication/E_NOT_OK
        arg EventStatus: type=Dem_EventStatusType, direction=IN
      operation ResetEventStatus: possible-error=PiDiagnosticMonitor_DEM_EVENT_StartApplication/E_NOT_OK
      error E_NOT_OK: error-code=1
    PiDcmDataService_DID_StartApplication
      operation WriteData
        arg Data: type=Dcm_Data2ByteType, direction=IN
        arg ErrorCode: type=Dcm_NegativeResponseCodeType, direction=OUT
      operation ReadData
        arg Data: type=Dcm_Data2ByteType, direction=OUT
      operation ConditionCheckRead
        arg ErrorCode: type=Dcm_NegativeResponseCodeType, direction=OUT
    PiDemDataService_DemDataElementClass_StartApplication
      operation ReadData
        arg Data: type=DataArray_Type_2, direction=OUT
    PiDemOpCycle_DemOperationCycle_0
      operation SetOperationCycleState: possible-error=PiDemOpCycle_DemOperationCycle_0/E_NOT_OK
        arg CycleState: type=Dem_OperationCycleStateType, direction=IN
      error E_NOT_OK: error-code=1
  sender receiver interface PiFSP1IndicationCmdL1_oFSP_1_2_Req_L1_oLIN00_c2c0fe90_Tx
    data DeFSP1IndicationCmdL1_oFSP_1_2_Req_L1_oLIN00_c2c0fe90_Tx: type=uint16
  sender receiver interface PiFSP2SwitchStatusL1_oFSP2_Frame_L1_oLIN00_ee70e556_Rx
    data DeFSP2SwitchStatusL1_oFSP2_Frame_L1_oLIN00_ee70e556_Rx: type=uint8
  client server interface PiMemoryAccessViolationState
    operation GetState
      arg State: type=boolean, direction=OUT
    operation Reset
  sender receiver interface PiTrustedData
    data DeValue: type=uint8
  client server interface PiTrustedDataInvalid
    operation Write
      arg Value: type=uint8, direction=IN
